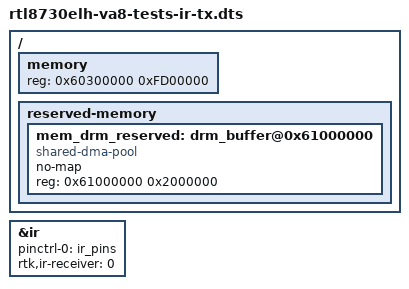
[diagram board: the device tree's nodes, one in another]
// SPDX-License-Identifier: GPL-2.0-only
/*
* Realtek DTS for IR TX test
*
* Copyright (C) 2023, Realtek Corporation. All rights reserved.
*/

/dts-v1/;

#include "rtl8730e.dtsi"
#include "rtl8730e-spi-nand-256m.dtsi"

/ {
	memory {
		device_type = "memory";
		// DRAM base address should be 1MB-aligned.
		reg = <0x60300000 0xFD00000>;  // 256MB -- exclude 3MB secure memory
	};
	reserved-memory {
		#address-cells = <1>;
		#size-cells = <1>;
		ranges;
		// reserver 32M mem for drm graphics , from 0x61000000 to 0x63000000
		mem_drm_reserved: drm_buffer@0x61000000 {
			compatible = "shared-dma-pool";
			no-map;
			reg = <0x61000000 0x2000000>;
			//linux,cma-default;
		};
	};
};

// Configure peripherals.
&ir {
	pinctrl-names = "default";
	pinctrl-0 = <&ir_pins>;
	rtk,ir-receiver = <0>; // 0: tx only; 1: rx only.
	status = "okay";
};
